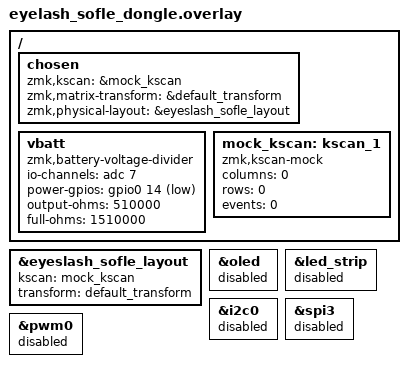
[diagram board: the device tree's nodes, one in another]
#include "eyelash_sofle.dtsi"

/ {
    chosen {
        zmk,kscan = &mock_kscan;
        zmk,matrix-transform = &default_transform;
        zmk,physical-layout = &eyeslash_sofle_layout;
        /delete-property/ zephyr,display;
        /delete-property/ zmk,underglow;
        /delete-property/ zmk,backlight;
    };

    /delete-node/ vbatt;

    vbatt: vbatt {
        compatible = "zmk,battery-voltage-divider";
        io-channels = <&adc 7>;
        power-gpios = <&gpio0 14 (GPIO_OPEN_DRAIN | GPIO_ACTIVE_LOW)>;
        output-ohms = <510000>;
        full-ohms = <1510000>;
    };

    mock_kscan: kscan_1 {
        compatible = "zmk,kscan-mock";
        columns = <0>;
        rows = <0>;
        events = <0>;
    };
};

&eyeslash_sofle_layout {
    kscan = <&mock_kscan>;
    transform = <&default_transform>;
};

&oled { status = "disabled"; };
&led_strip { status = "disabled"; };
&i2c0 { status = "disabled"; };
&spi3 { status = "disabled"; };
&pwm0 { status = "disabled"; };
